# psoc4000t register map
Vendor: Cypress Semiconductor; Series: PSoC4000T; File version: 1.0
CPU: CM0PLUS r0p1, little endian, no MPU, no FPU, VTOR, 2 interrupt priority bits
Registers are 32-bit, read-write, reset 0x0 unless marked. A register's access mark holds for its fields unless they carry their own. Offsets are from the block's base; [hi:lo] are bit positions; lines under a group give offsets from that group; {n}, {i} and the like mark numbered series; 'fields as' and 'values as' point back to an identical list.

## MSCLP0 (part 2 of 3) — Low Power MultiSense Converter
Base 0x40290000
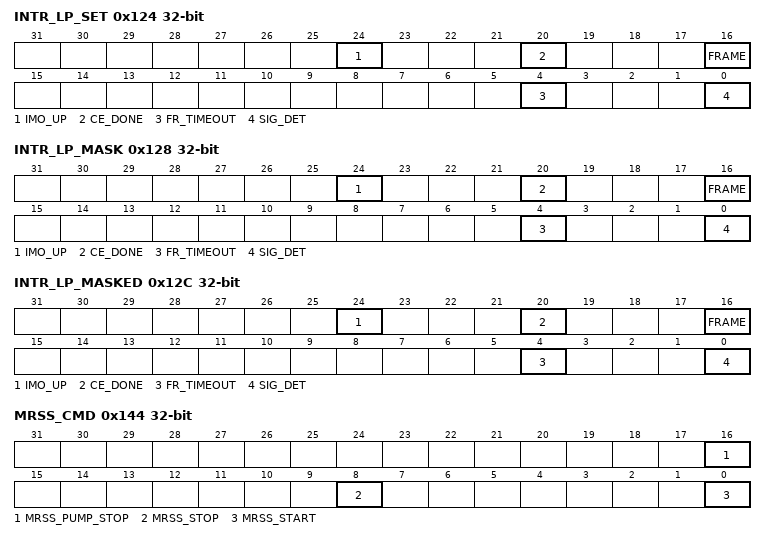
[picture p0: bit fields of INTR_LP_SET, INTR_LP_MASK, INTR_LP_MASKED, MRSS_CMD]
0x124 INTR_LP_SET — Low Power Interrupt Set Register
  [24] IMO_UP — Write with '1' to set corresponding bit in interrupt request register (a write of '0' has no effect).
  [20] CE_DONE — Write with '1' to set corresponding bit in interrupt request register (a write of '0' has no effect).
  [16] FRAME — Write with '1' to set corresponding bit in interrupt request register (a write of '0' has no effect).
  [4] FR_TIMEOUT — Write with '1' to set corresponding bit in interrupt request register (a write of '0' has no effect).
  [0] SIG_DET — Write with '1' to set corresponding bit in interrupt request register (a write of '0' has no effect).
0x128 INTR_LP_MASK — Low Power Interrupt Mask Register
  [24] IMO_UP — Mask bit for corresponding bit in interrupt cause register.
  [20] CE_DONE — Mask bit for corresponding bit in interrupt cause register.
  [16] FRAME — Mask bit for corresponding bit in interrupt cause register.
  [4] FR_TIMEOUT — Mask bit for corresponding bit in interrupt cause register.
  [0] SIG_DET — Mask bit for corresponding bit in interrupt cause register.
0x12C INTR_LP_MASKED ro — Low Power Interrupt Masked Register
  [24] IMO_UP — Logical AND of corresponding INTR_LP and INTR_LP_MASK bits.
  [20] CE_DONE — Logical AND of corresponding INTR_LP and INTR_LP_MASK bits.
  [16] FRAME — Logical AND of corresponding INTR_LP and INTR_LP_MASK bits.
  [4] FR_TIMEOUT — Logical AND of corresponding INTR_LP and INTR_LP_MASK bits.
  [0] SIG_DET — Logical AND of corresponding INTR_LP and INTR_LP_MASK bits.
0x140 WAKEUP_CMD — Wakeup Command Register
  [0] START_FRAME_AOS — Set by firmware to initiate frame scanning by the LP-AoS FSM (required for DEEP_SLEEP scanning). When detected, hardware clears the bit down and the LP-AoS FSM periodically scans all valid sensor configurations programmed in the sensor configuration storage starting from FRAME_CFG_START_ADDR. AoS Sequencer FSM clears this bit on egress from IDLE. If START_FRAME_AOS is set by firmware when FSM is not in IDLE, the hardware must hold the bit set to allow for 'pending' frame behaviour. Note that a rising edge on this bit also creates a 2x cycle clk_lf pulse on the msc_ext_frm_start_out signal (when EXT_FRAME_START_MODE = DISABLED). The corresponding msc_ext_frm_start_out_en is controlled by CTL.ENABLED.
0x144 MRSS_CMD — MRSS Command Register
  [16] MRSS_PUMP_STOP — Stop the MRSS pump resource. The ability to shut off the MRSS pump allows for power saving when MSCv3LP is in a standby state (CTL.ENABLED = 0) not scanning and hence no pump is needed. In this case the MRSS reference and IMO remain on so firmware may access MMIO in the SNS_STRUCTLP register bank. MRSS_STOP is used in the case where the entire MRSS is to be shut down. This bit is always read as 0.
  [8] MRSS_STOP — Stop the MRSS resources (shut down the reference, IMO and pump). This bit is always read as 0.
  [0] MRSS_START — Start the MRSS local resources. Activates logic on the clk_lf domain to boot up the MRSS resources. The boot up happens in sequence according to required timing specifications with reference, IMO (at frequencey IMO_CTL.FREQ) and pump (based on PUMP_CTL.PUMP_MODE). Firmware Rule: MRSS_START must be set by firmware to access any MMIO on the local IMO domain (SNS_STRUCTLP). This is not necessary in cases where the hardware has alread turned on the MRSS IMO and left it on (e.g. after DEEP_SLEEP interrupt the hardware leaves the IMO on with the expectation is that firmware intends to read SNS_STRUCTLP after such an interrupt).
0x180 MRSS_STATUS ro
  [0] MRSS_UP — Status bit to indicate whether the MRSS resources are booted or not. This booting may occur as the result of firmware intervention via MRSS_START/STOP or hardware based control via the LP-AoS FSM.
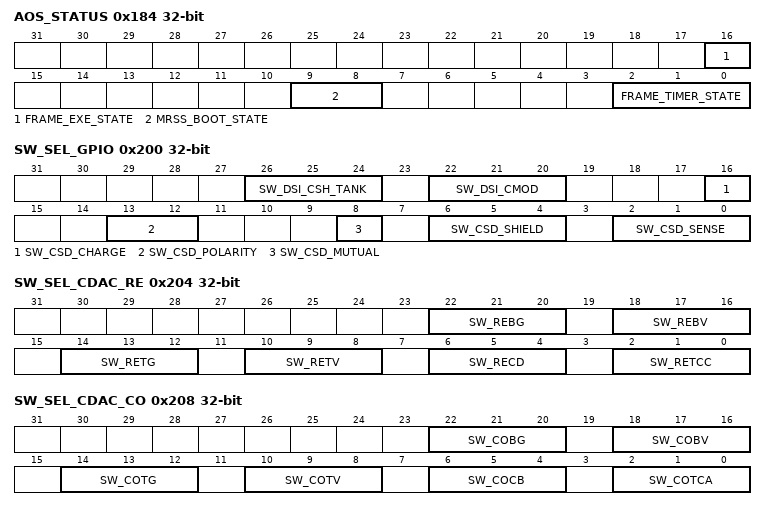
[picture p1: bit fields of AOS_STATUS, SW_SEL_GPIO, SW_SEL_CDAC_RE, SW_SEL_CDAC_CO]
0x184 AOS_STATUS ro
  [16] FRAME_EXE_STATE — LP-AoS Frame Execute FSM state. FSM runs on clk_imo_msc and no CDC implemented to AOS_STATUS (clk_sys).
    0=IDLE (N/A); 1=LP_EXE_FRAME (N/A)
  [9:8] MRSS_BOOT_STATE — LP-AoS MRSS Boot FSM state. FSM runs on clk_lf and no CDC implemented to AOS_STATUS (clk_sys).
    0=IDLE (N/A); 1=START_REF (N/A); 2=START_IMO (N/A); 3=START_PUMP (N/A)
  [2:0] FRAME_TIMER_STATE — LP-AoS Frame Timer FSM state. FSM runs on clk_lf and no CDC implemented to AOS_STATUS (clk_sys).
    0=IDLE (N/A); 1=WAIT_FRAME_INTERVAL (N/A); 2=WAIT_IMO (N/A); 3=LP_START_FRAME (N/A); 4=LP_WAIT_FRAME (N/A)
0x200 SW_SEL_GPIO — GPIO Switch Control
  [26:24] SW_DSI_CSH_TANK — MUX select for dsi_csh_tank waveform. if CMOD_SEL = CMOD_12 | CMOD_1 dsi_csh_tank[0] = Decode SW_DSI_CSH_TANK to select appropriate dsi_csh_tank waveform. dsi_csh_tank[1] = 0. if CMOD_SEL = CMOD_34 | CMOD_3 dsi_csh_tank[0] = 0. dsi_csh_tank[1] = Decode SW_DSI_CSH_TANK to select appropriate dsi_csh_tank waveform. This is assuming that: dsi_csh_tank[0] is routed to cmod2 dsi_csh_tank[1] is routed to cmod4 Hardware Overriding: Note that hardware overrides MMIO setting for dsi_csh_tank and sets it 1 during the INIT_SHORT state if using GPIO sensors (SW_DSI_CMOD != OPEN || SW_DSI_CSHTANK != OPEN).
    0=LOGIC_0 (N/A); 1=LOGIC_1 (N/A); 2=CHOP_PH0_PH1 (chop == 1 ? ph0 : ph1); 3=CHOP_PH1_PH3 (chop == 1 ? ph1 : ph3); 4=PH1 (N/A)
  [22:20] SW_DSI_CMOD — MUX select for dsi_cmod waveform. if CMOD_SEL = CMOD_12 | CMOD_1 dsi_cmod[0] = Decode SW_DSI_CMOD to select appropriate dsi_cmod waveform. dsi_cmod[1] = 0. if CMOD_SEL = CMOD_34 | CMOD_3 dsi_cmod[0] = 0. dsi_cmod[1] = Decode SW_DSI_CMOD to select appropriate dsi_cmod waveform. This is assuming that: dsi_cmod[0] is routed to cmod1 dsi_cmod[1] is routed to cmod3 Hardware Overriding: Note that hardware overrides MMIO setting for dsi_cmod and sets it 1 during the INIT_SHORT state if using GPIO sensors (SW_DSI_CMOD != OPEN || SW_DSI_CSHTANK != OPEN).
    0=LOGIC_0 (N/A); 1=LOGIC_1 (N/A); 2=CHOP_PH1_PH0 (chop == 1 ? ph1 : ph0); 3=CHOP_PH3_PH1 (chop == 1 ? ph3 : ph1); 4=PH0 (N/A)
  [16] SW_CSD_CHARGE — MUX select for csd_charge waveform.
    0=LOGIC_0 (N/A); 1=LOGIC_1 (N/A)
  [13:12] SW_CSD_POLARITY — MUX select for csd_polarity waveform.
    0=LOGIC_0 (N/A); 1=LOGIC_1 (N/A); 2=PH0_OR_PH1 (N/A)
  [8] SW_CSD_MUTUAL — MUX select for csd_mutual waveform.
    0=LOGIC_0 (N/A); 1=LOGIC_1 (N/A)
  [6:4] SW_CSD_SHIELD — MUX select for csd_shield waveform.
    0=LOGIC_0 (N/A); 1=LOGIC_1 (N/A); 2=PH0 (N/A); 3=PH1 (N/A); 4=PH0_OR_PH3 (N/A); 5=PH0_OR_FS2PH1_AND_PH1_OR_PH3 (ph0 || [Fs2_ph1 && (ph1 || ph3)]); 6=PH1X (N/A)
  [2:0] SW_CSD_SENSE — MUX select for csd_sense waveform.
    0=LOGIC_0 (N/A); 1=LOGIC_1 (N/A); 2=PH0 (N/A); 3=PH1 (N/A); 4=PH0_OR_PH3 (N/A); 5=PH0X (N/A); 6=PH1X (N/A)
0x204 SW_SEL_CDAC_RE — Reference CAPDAC Switch Control
  [22:20] SW_REBG — Reference CAPDAC bottom plate to vssa_q Switch. Firmware Rule: Do not program REBV and REBG such that they are closed simultaneously. Hardware Overriding: See SEL_RE register description.
    0=OPEN (sel = 00); 1=CLOSED (sel = 01); 2=CLK (sel = 10 (clk_reffb)); 3=CLK_BAR (sel = 11 (!clk_reffb)); 4=PH1X (DFT mode (ph1X ? sel = 01 : sel = 00))
  [18:16] SW_REBV — Reference CAPDAC bottom plate to vdda_q Switch. Firmware Rule: Do not program REBV and REBG such that they are closed simultaneously. Hardware Overriding: See SEL_RE register description.
    0=OPEN (sel = 00); 1=CLOSED (sel = 01); 2=CLK (sel = 10 (clk_reffb)); 3=CLK_BAR (sel = 11 (!clk_reffb)); 4=PH0X (DFT mode (ph0X ? sel = 01 : sel = 00))
  [14:12] SW_RETG — Reference CAPDAC top plate to vssa_q Switch. Firmware Rule: Do not program RETV and RETG such that they are closed simultaneously. Hardware Overriding: See SEL_RE register description.
    0=OPEN (sel = 00); 1=CLOSED (sel = 01); 2=CLK (sel = 10 (clk_reffb)); 3=CLK_BAR (sel = 11 (!clk_reffb)); 4=PH0 (DFT mode (ph0 ? sel = 01 : sel = 00)); 5=PH2 (DFT mode (ph2 ? sel = 01 : sel = 00))
  [10:8] SW_RETV — Reference CAPDAC top plate to vdda_q Switch. Firmware Rule: Do not program RETV and RETG such that they are closed simultaneously. Hardware Overriding: See SEL_RE register description.
    values as SW_RETG
  [6:4] SW_RECD — Reference CAPDAC to CSD Bus D Switch. Hardware Overriding: See SEL_RE register description.
    0=OPEN (sel = 00); 1=CLOSED (sel = 01); 2=CHOP_CLK_BAR (chop == 0 ? sel = 10 (clk_reffb) : sel = 11 (!clk_reffb)); 3=CHOP_CLK (chop == 1 ? sel = 10 (clk_reffb) : sel = 11 (!clk_reffb)); 4=PH1 (DFT mode (ph1 ? sel = 01 : sel = 00)); 5=PH3 (DFT mode (ph3 ? sel = 01 : sel = 00))
  [2:0] SW_RETCC — Reference CAPDAC top plate to CSD Bus C Switch. Hardware Overriding: See SEL_RE register description.
    0=OPEN (sel = 00); 1=CLOSED (sel = 01); 2=CHOP_CLK_BAR (chop == 0 ? sel = 10 (clk_reffb) : sel = 11 (!clk_reffb)); 3=CHOP_CLK (chop == 1 ? sel = 10 (clk_reffb) : sel = 11 (!clk_reffb)); 4=PH1 (DFT mode (ph1 ? sel = 01 : sel = 00)); 5=PH3 (DFT mode (ph3 ? sel = 01 : sel = 00)); 6=PH0 (DFT mode (ph0 ? sel = 01 : sel = 00))
0x208 SW_SEL_CDAC_CO — Compensation CAPDAC Switch Control
  [22:20] SW_COBG — Compensation CAPDAC bottom plate to vssa_q Switch. Firmware Rule: Do not program COBV and COBG such that they are closed simultaneously. Hardware Overriding: See SEL_CO, COMP_BLANKING_EN register description.
    0=OPEN (sel = 00); 1=CLOSED (sel = 01); 2=CLK (sel = 10 (clk_comp)); 3=CLK_BAR (sel = 11 (!clk_comp)); 4=PH1X (DFT mode (ph1X ? sel = 01 : sel = 00))
  [18:16] SW_COBV — Compensation CAPDAC bottom plate to vdda_q Switch. Firmware Rule: Do not program COBV and COBG such that they are closed simultaneously. Hardware Overriding: See SEL_CO, COMP_BLANKING_EN register description.
    0=OPEN (sel = 00); 1=CLOSED (sel = 01); 2=CLK (sel = 10 (clk_comp)); 3=CLK_BAR (sel = 11 (!clk_comp)); 4=PH0X (DFT mode (ph0X ? sel = 01 : sel = 00))
  [14:12] SW_COTG — Compensation CAPDAC top plate to vssa_q Switch. Firmware Rule: Do not program COTV and COTG such that they are closed simultaneously. Hardware Overriding: See SEL_CO, COMP_BLANKING_EN register description.
    values as SW_SEL_CDAC_RE.SW_RETG
  [10:8] SW_COTV — Compensation CAPDAC top plate to vdda_q Switch. Firmware Rule: Do not program COTV and COTG such that they are closed simultaneously. Hardware Overriding: See SEL_CO, COMP_BLANKING_EN register description.
    values as SW_SEL_CDAC_RE.SW_RETG
  [6:4] SW_COCB — Compensation CAPDAC to CSD Bus B Switch. Hardware Overriding: Note during the PRO_OFFSET state the following autonomous overriding occurs: (compout_sync ^ CHOP_POL) ? [sel = 10 (clk_comp) ] : [sel = 11 (!clk_comp)]. Note that the CHOP_POL above is the hardware copy of the current chop polarity. Additionally see SEL_CO, COMP_BLANKING_EN register description.
    0=OPEN (sel = 00); 1=CLOSED (sel = 01); 2=CHOP_CLK_BAR (chop == 0 ? sel = 10 (clk_comp) : sel = 11 (!clk_comp)); 3=CHOP_CLK (chop == 1 ? sel = 10 (clk_comp) : sel = 11 (!clk_comp)); 4=PH1 (DFT mode (ph1 ? sel = 01 : sel = 00)); 5=PH3 (DFT mode (ph3 ? sel = 01 : sel = 00))
  [2:0] SW_COTCA — Compensation CAPDAC top plate to CSD Bus A Switch. Hardware Overriding: Note during the PRO_OFFSET state the following autonomous overriding occurs: (compout_sync ^ CHOP_POL) ? [sel = 11 (!clk_comp) ] : [sel = 10 (clk_comp)]. Note that the CHOP_POL above is the hardware copy of the current chop polarity. Additionally see SEL_CO, COMP_BLANKING_EN register description.
    0=OPEN (sel = 00); 1=CLOSED (sel = 01); 2=CHOP_CLK_BAR (chop == 0 ? sel = 10 (clk_comp) : sel = 11 (!clk_comp)); 3=CHOP_CLK (chop == 1 ? sel = 10 (clk_comp) : sel = 11 (!clk_comp)); 4=PH1 (DFT mode (ph1 ? sel = 01 : sel = 00)); 5=PH3 (DFT mode (ph3 ? sel = 01 : sel = 00)); 6=PH0 (DFT mode (ph0 ? sel = 01 : sel = 00))
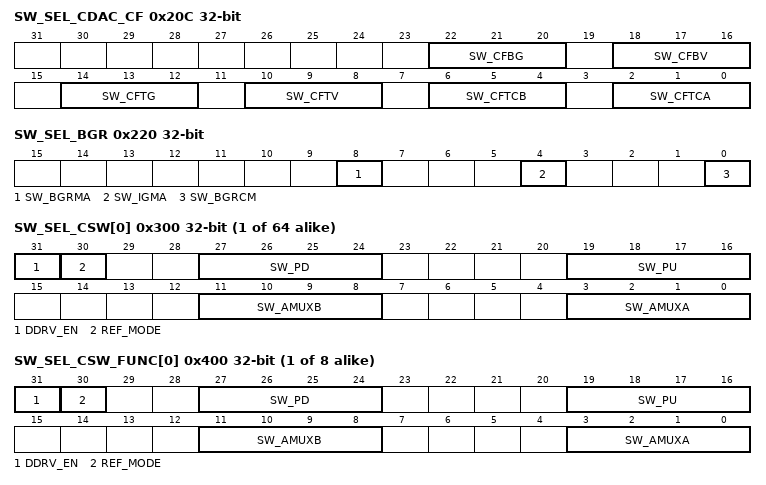
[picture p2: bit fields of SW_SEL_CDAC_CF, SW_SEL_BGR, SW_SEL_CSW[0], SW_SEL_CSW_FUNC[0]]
0x20C SW_SEL_CDAC_CF — Fine CAPDAC Switch Control
  [22:20] SW_CFBG — Fine CAPDAC bottom plate to vssa_q Switch. Firmware Rule: Do not program CFBV and CFBG such that they are closed simultaneously. Hardware Overriding: See SEL_CF, COMP_BLANKING_EN register description.
    0=OPEN (sel = 00); 1=CLOSED (sel = 01); 2=CLK (FINE_MODE == REFERENCE ? sel = 10 (clk_reffb) : sel = 10 (clk_comp)); 3=CLK_BAR (FINE_MODE == REFERENCE ? sel = 11 (!clk_reffb) : sel = 11 (!clk_comp)); 4=PH1X (DFT mode (ph1X ? sel = 01 : sel = 00))
  [18:16] SW_CFBV — Fine CAPDAC bottom plate to vdda_q Switch. Firmware Rule: Do not program CFBV and CFBG such that they are closed simultaneously. Hardware Overriding: See SEL_CF, COMP_BLANKING_EN register description.
    0=OPEN (sel = 00); 1=CLOSED (sel = 01); 2=CLK (FINE_MODE == REFERENCE ? sel = 10 (clk_reffb) : sel = 10 (clk_comp)); 3=CLK_BAR (FINE_MODE == REFERENCE ? sel = 11 (!clk_reffb) : sel = 11 (!clk_comp)); 4=PH0X (DFT mode (ph0X ? sel = 01 : sel = 00))
  [14:12] SW_CFTG — Fine CAPDAC top plate to vssa_q Switch. Firmware Rule: Do not program CFTV and CFTG such that they are closed simultaneously. Hardware Overriding: See SEL_CF register description.
    0=OPEN (sel = 00); 1=CLOSED (sel = 01); 2=CLK (sel = 10 [(FINE_MODE == REFERENCE) ? clk_reffb : clk_comp]); 3=CLK_BAR (sel = 11 [(FINE_MODE == REFERENCE) ? !clk_reffb : !clk_comp]); 4=PH0 (DFT mode (ph0 ? sel = 01 : sel = 00)); 5=PH2 (DFT mode (ph2 ? sel = 01 : sel = 00))
  [10:8] SW_CFTV — Fine CAPDAC top plate to vdda_q Switch. Firmware Rule: Do not program CFTV and CFTG such that they are closed simultaneously. Hardware Overriding: See SEL_CF, COMP_BLANKING_EN register description.
    values as SW_CFTG
  [6:4] SW_CFTCB — Fine CAPDAC top plate to CSD Bus B Switch. Hardware Overriding: Note during the PRO_OFFSET state the following autonomous overriding occurs if FINE_MODE = COMPENSATION: (compout_sync ^ CHOP_POL) ? [sel = 10 (clk_comp) ] : [sel = 11 (!clk_comp)]. Note that the CHOP_POL above is the hardware copy of the current chop polarity. Hardware Overriding: See SEL_CO, COMP_BLANKING_EN register description.
    0=OPEN (sel = 00); 1=CLOSED (sel = 01); 2=CHOP_CLK_BAR (case({chop,FINE_MODE}) {1,REFERENCE} : sel = 11 (!clk_reffb) {1,COMPENSATION} : sel = 11 (!clk_comp) {0,REFERENCE} : sel = 10 (clk_reffb) {0,COMPENSATION} : sel = 10 (clk_comp)); 3=CHOP_CLK (case({chop,FINE_MODE}) {1,REFERENCE} : sel = 10 (clk_reffb) {1,COMPENSATION} : sel = 10 (clk_comp) {0,REFERENCE} : sel = 11 (!clk_reffb) {0,COMPENSATION} : sel = 11 (!clk_comp)); 4=PH1 (DFT mode (ph1 ? sel = 01 : sel = 00)); 5=PH3 (DFT mode (ph3 ? sel = 01 : sel = 00)); 6=PH0 (DFT mode (ph0 ? sel = 01 : sel = 00))
  [2:0] SW_CFTCA — Fine CAPDAC top plate to CSD Bus A Switch. Hardware Overriding: Note during the PRO_OFFSET state the following autonomous overriding occurs if FINE_MODE = COMPENSATION: (compout_sync ^ CHOP_POL) ? [sel = 11 (!clk_comp) ] : [sel = 10 (clk_comp)]. Note that the CHOP_POL above is the hardware copy of the current chop polarity. Additionally see SEL_CF, COMP_BLANKING_EN register description.
    values as SW_CFTCB
0x220 SW_SEL_BGR — Bandgap Reference Switch Control
  [all] fields
    0=OPEN (N/A); 1=CLOSED (N/A)
  [8] SW_BGRMA — Connect buffered 1.2V reference to ADFT pin via AMUXBUSA. For DFT purposes.
  [4] SW_IGMA — Connect 48uA ganged IREF to ADFT pin via AMUXBUSA. For DFT purposes.
  [0] SW_BGRCM — BandGap reference to Comparator minus terminal switch. This switch can be used for firmware vdda level detection to facilitate appropriate configuration of the local pump and pump regulator.
{0x300+4i} SW_SEL_CSW[{i}] (i=0..63) — CapSense Sensor Switch Control
  [31] DDRV_EN — MutliSense GPIO Sensor N digital driver enable in MSC specific GPIO. Firmware Rule: When using the digital driver, the GPIO MSC analog cannot be used (GPIO port register MSC_ANA.DATAx for port pin x should be set 0).
    0=DISABLED (N/A); 1=ENABLED (N/A)
  [30] REF_MODE — MutliSense GPIO Sensor N is used as a reference. Hardware Overriding: If REF_MODE = 0, SW_AMUXA, SW_AMUXB, SW_PU and SW_PD are all forced OPEN duing PRO_OFFSET, PRO_WAIT, EPILOGUE and POST_EPI to disconnect the sensor.
    0=DISABLED (N/A); 1=ENABLED (N/A)
  [27:24] SW_PD — MultiSense GPIO Sensor N pull down to vssa_q Switch. Switch exists in MSC specific GPIO. Firmware Rule: Do not program PU and PD such that they are closed simultaneously. Hardware Overriding: If this sensor is a FW CSX TXP pin (SW_PU == PH0X && SW_PD == PH1X), SW_PD is CLOSED during INIT_CMOD and INIT_SHORT if in full wave mode (CMOD_SEL = CMOD_12||CMOD_34 && INIT_MODE = REFERENCE_VDDA).
    0=OPEN (N/A); 1=CLOSED (N/A); 2=PH0 (N/A); 3=PH1 (N/A); 4=PH2 (N/A); 5=PH1_OR_PH3 (N/A); 6=PH2_OR_PH3 (N/A); 7=PH0X (N/A); 8=PH1X (N/A); 9=PH2_OR_FS2PH1_AND_PH1_OR_PH3 (ph2 || [Fs2_ph1 && (ph1 || ph3)]); 10=CLK_BAR (clk_extfb_bar); 11=PH1_OR_PH2 (Note SENSE_DUTY_CTL digital non-overlap control has no impact on this waveform.); 12=PH0_OR_PH3 (Note SENSE_DUTY_CTL digital non-overlap control has no impact on this waveform.)
  [19:16] SW_PU — MultiSense GPIO Sensor N pull up to vdda_q Switch. Switch exists in MSC specific GPIO. Also drives the MSC specific GPIO digital driver (enable controlled by DDRV_EN). Firmware Rule: Do not program PU and PD such that they are closed simultaneously. Hardware Overriding: If this sensor is a FW CSX TXN pin (SW_PU == PH1X && SW_PD == PH0X), SW_PU is CLOSED during INIT_CMOD and INIT_SHORT if in full wave mode (CMOD_SEL = CMOD_12||CMOD_34 && INIT_MODE = REFERENCE_VDDA).
    0=OPEN (N/A); 1=CLOSED (N/A); 2=PH0 (N/A); 3=PH1 (N/A); 4=PH2 (N/A); 5=PH0_OR_PH1 (N/A); 6=PH0X (N/A); 7=PH1X (N/A); 8=PH0_OR_FS2PH0_AND_PH1_OR_PH3 (ph0 || [Fs2_ph0 && (ph1 || ph3)]); 9=CLK (clk_extfb); 10=PH0X_BAR; 11=PH1_OR_PH2 (Note SENSE_DUTY_CTL digital non-overlap control has no impact on this waveform.); 12=PH0_OR_PH3 (Note SENSE_DUTY_CTL digital non-overlap control has no impact on this waveform.)
  [11:8] SW_AMUXB — MultiSense GPIO Sensor N to AMUXBUSB Switch. Switch exists in MSC specific GPIO. Hardware Overriding: If this sensor is a full wave CSD RX pin or a FW CSD Cs pin ((CMOD_SEL = CMOD_12||CMOD_34) && INIT_MODE = REFERENCE_VDDA && SW_AMUXA != OPEN), then SW_AMUXB is set CLOSED during INIT_CMOD.
    0=OPEN (N/A); 1=CLOSED (N/A); 2=CHOP_TWO_PHASE (chop == 0 ? ph1 : ph0); 3=CHOP_FOUR_PHASE (chop == 0 ? ph3 : ph1); 4=CHOP_MPSC_D (chop == 0 ? ph1 : ph3); 5=CHOP_MPRX (chop == 0 ? ph0 : ph1); 6=PH0 (N/A); 7=PH2 (N/A); 8=CHOP_CLK_BAR (chop == 0 ? clk_extfb : clk_extfb_bar); 9=CHOP_CLK (chop == 1 ? clk_extfb : clk_extfb_bar); 10=PH1_OR_PH3 (N/A)
  [3:0] SW_AMUXA — MultiSense GPIO Sensor N to AMUXBUSA Switch. Switch exists in MSC specific GPIO. Hardware Overriding: Note that hardware overrides MMIO setting for SW_AMUXA and sets it CLOSED during the INIT_SHORT state if MMIO has programmed SW_AMUXA != OPEN (i.e. this sensor is being used). The same overriding applies during INIT_CMOD, but only in half-wave mode (CMOD_SEL = CMOD_1 or CMOD_3).
    0=OPEN (N/A); 1=CLOSED (N/A); 2=CHOP_TWO_PHASE (chop == 0 ? ph0 : ph1); 3=CHOP_FOUR_PHASE (chop == 0 ? ph1 : ph3); 4=CHOP_MPSC_D (chop == 0 ? ph3 : ph1); 5=CHOP_MPRX (chop == 0 ? ph1 : ph0); 6=PH1 (N/A); 7=PH3 (N/A); 8=CHOP_CLK_BAR (chop == 0 ? clk_extfb : clk_extfb_bar); 9=CHOP_CLK (chop == 1 ? clk_extfb : clk_extfb_bar); 10=PH1_OR_PH3 (N/A)
{0x400+4i} SW_SEL_CSW_FUNC[{i}] (i=0..7) — CapSense Sensor Switch Control Global Functions
  [31] DDRV_EN — MutliSense GPIO Sensor N digital driver enable in MSC specific GPIO. Firmware Rule: When using the digital driver, the GPIO MSC analog cannot be used (GPIO port register MSC_ANA.DATAx for port pin x should be set 0).
    0=DISABLED (N/A); 1=ENABLED (N/A)
  [30] REF_MODE — MultiSense GPIO Sensor is used as a reference. Hardware Overriding: If REF_MODE = 0, SW_AMUXA, SW_AMUXB, SW_PU and SW_PD are all forced OPEN duing PRO_OFFSET, PRO_WAIT, EPILOGUE and POST_EPI to disconnect the sensor.
    0=DISABLED (N/A); 1=ENABLED (N/A)
  [27:24] SW_PD — MultiSense GPIO Sensor pull down to vssa_q Switch. Switch exists in MSC specific GPIO. Firmware Rule: Do not program PU and PD such that they are closed simultaneously. Hardware Overriding: If this sensor is a FW CSX TXP pin (SW_PU == PH0X && SW_PD == PH1X), SW_PD is CLOSED during INIT_CMOD and INIT_SHORT if in full wave mode (CMOD_SEL = CMOD_12||CMOD_34 && INIT_MODE = REFERENCE_VDDA).
    values as SW_SEL_CSW[0].SW_PD
  [19:16] SW_PU — MultiSense GPIO Sensor pull up to vdda_q Switch. Switch exists in MSC specific GPIO. Also drives the MSC specific GPIO digital driver (enable controlled by DDRV_EN). Firmware Rule: Do not program PU and PD such that they are closed simultaneously. Hardware Overriding: If this sensor is a FW CSX TXN pin (SW_PU == PH1X && SW_PD == PH0X), SW_PU is CLOSED during INIT_CMOD and INIT_SHORT if in full wave mode (CMOD_SEL = CMOD_12||CMOD_34 && INIT_MODE = REFERENCE_VDDA).
    values as SW_SEL_CSW[0].SW_PU
  [11:8] SW_AMUXB — MultiSense GPIO Sensor N to AMUXBUSB Switch. Switch exists in MSC specific GPIO. Hardware Overriding: If this sensor is a full wave CSD RX pin or a FW CSD Cs pin ((CMOD_SEL = CMOD_12||CMOD_34) && INIT_MODE = REFERENCE_VDDA && SW_AMUXA != OPEN), then SW_AMUXB is set CLOSED during INIT_CMOD.
    values as SW_SEL_CSW[0].SW_AMUXB
  [3:0] SW_AMUXA — MultiSense GPIO Sensor to AMUXBUSA Switch. Switch exists in MSC specific GPIO. Hardware Overriding: Note that hardware overrides MMIO setting for SW_AMUXA and sets it CLOSED during the INIT_SHORT state if MMIO has programmed SW_AMUXA != OPEN (i.e. this sensor is being used). The same overriding applies during INIT_CMOD, but only in half-wave mode (CMOD_SEL = CMOD_1 or CMOD_3).
    values as SW_SEL_CSW[0].SW_AMUXA
0x500 CSW_CTL_LO — CapSense Sensor Switch Control Low
  [31:0] CSW_FUNC_MODE — Select between SW_SEL_CSW[x] and SW_SEL_CSW_FUNC. CSW_FUNC_MODE[x] = 0: Use SW_CSW_CTL for control MUX x. CSW_FUNC_MODE[x] = 1: Use SW_SEL_CSW_FUNC[y] for control MUX x as selected by y = {SW_SEL_CSW_MASK2[x],SW_SEL_CSW_MASK1[x],SW_SEL_CSW_MASK0[x]}.
0x504 CSW_CTL_HI — CapSense Sensor Switch Control High
  fields as CSW_CTL_LO
{0x600+0x40*i} MODE[{i}] (i=0..2) group — Sense Mode Configuration Structure
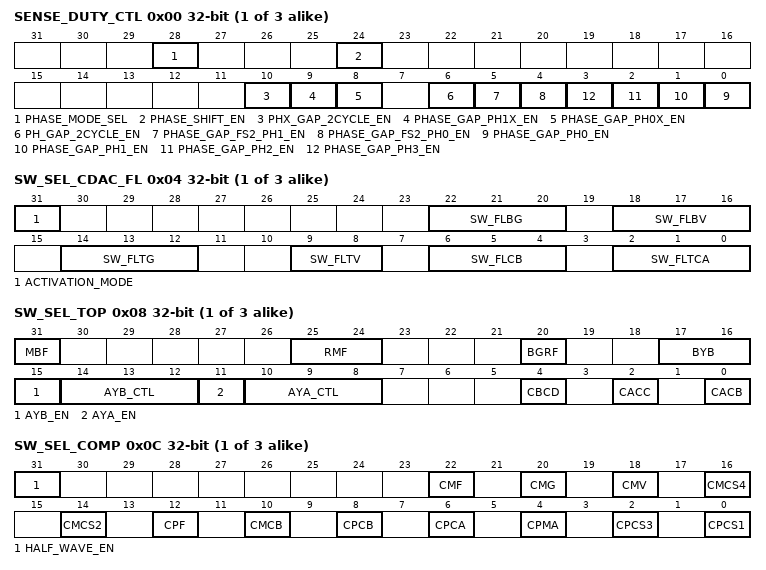
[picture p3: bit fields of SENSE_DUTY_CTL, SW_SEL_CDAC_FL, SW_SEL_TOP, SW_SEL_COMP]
  0x00 SENSE_DUTY_CTL — Sense Clock Duty Cycle Control
    [28] PHASE_MODE_SEL — Select 4-phase or 2-phase mode. '0': Four phase. '1': Two phase.
      0=FOUR_PHASE (N/A); 1=TWO_PHASE (N/A)
    [24] PHASE_SHIFT_EN — Enable phase shift logic that generates the Ph0X and Ph1X waveforms. Used for inductive and impedance sensing. If enabled, PHASE_SHIFT_CYCLES must be > 0.
      0=DISABLED (N/A); 1=ENABLED (N/A)
    [10] PHX_GAP_2CYCLE_EN — If set, applies a two cycle gap on ph0X/ph1X if the corresponding PHASE_GAP_*_EN is set.
      0=ONE_CYCLE (N/A); 1=TWO_CYCLE (N/A)
    [9] PHASE_GAP_PH1X_EN — Decide whether clk_mod cycle non-overlap gap is applied at the end of ph1x. PHASE_GAP_PH1X_EN = 0 -> No gap. PHASE_GAP_PH1X_EN = 1 && PHX_GAP_2CYCLE_EN = 0 -> 1x cycle gap. PHASE_GAP_PH1X_EN = 1 && PHX_GAP_2CYCLE_EN = 1 -> 2x cycle gap. Does not apply to signals controlled by SW_SEL_CSD and SW_SEL_DSI since GPIO has in-built non-overlap circuitry.
      0=DISABLED (N/A); 1=ENABLED (N/A)
    [8] PHASE_GAP_PH0X_EN — Decide whether clk_mod cycle non-overlap gap is applied at the end of ph0x. PHASE_GAP_PH0X_EN = 0 -> No gap. PHASE_GAP_PH0X_EN = 1 && PHX_GAP_2CYCLE_EN = 0 -> 1x cycle gap. PHASE_GAP_PH0X_EN = 1 && PHX_GAP_2CYCLE_EN = 1 -> 2x cycle gap. Does not apply to signals controlled by SW_SEL_CSD and SW_SEL_DSI since GPIO has in-built non-overlap circuitry.
      0=DISABLED (N/A); 1=ENABLED (N/A)
    [6] PH_GAP_2CYCLE_EN — If set, applies a two cycle gap on ph0/ph1/ph2/ph3/Fs2_ph0/Fs2_ph1 if the corresponding PHASE_GAP_*_EN is set.
      0=ONE_CYCLE (N/A); 1=TWO_CYCLE (N/A)
    [5] PHASE_GAP_FS2_PH1_EN — Decide whether clk_mod cycle non-overlap gap is applied at the end of Fs2_ph0. PHASE_GAP_FS2_PH1_EN = 0 -> No gap. PHASE_GAP_FS2_PH1_EN = 1 && PH_GAP_2CYCLE_EN = 0 -> 1x cycle gap. PHASE_GAP_FS2_PH1_EN = 1 && PH_GAP_2CYCLE_EN = 1 -> 2x cycle gap. Does not apply to signals controlled by SW_SEL_CSD and SW_SEL_DSI since GPIO has in-built non-overlap circuitry.
      0=DISABLED (N/A); 1=ENABLED (N/A)
    [4] PHASE_GAP_FS2_PH0_EN — Decide whether clk_mod cycle non-overlap gap is applied at the end of Fs2_ph0. PHASE_GAP_FS2_PH0_EN = 0 -> No gap. PHASE_GAP_FS2_PH0_EN = 1 && PH_GAP_2CYCLE_EN = 0 -> 1x cycle gap. PHASE_GAP_FS2_PH0_EN = 1 && PH_GAP_2CYCLE_EN = 1 -> 2x cycle gap. Does not apply to signals controlled by SW_SEL_CSD and SW_SEL_DSI since GPIO has in-built non-overlap circuitry.
      0=DISABLED (N/A); 1=ENABLED (N/A)
    [n] PHASE_GAP_PH{n}_EN (n=0..3) — Decide whether clk_mod cycle non-overlap gap is applied at the end of ph{n}. PHASE_GAP_PH{n}_EN = 0 -> No gap. PHASE_GAP_PH{n}_EN = 1 && PH_GAP_2CYCLE_EN = 0 -> 1x cycle gap. PHASE_GAP_PH{n}_EN = 1 && PH_GAP_2CYCLE_EN = 1 -> 2x cycle gap. Does not apply to signals controlled by SW_SEL_CSD and SW_SEL_DSI since GPIO has in-built non-overlap circuitry.
      0=DISABLED (N/A); 1=ENABLED (N/A)
  0x04 SW_SEL_CDAC_FL — Flatspot/Dither CAPDAC Switch Control
    [31] ACTIVATION_MODE — Activation event for Dither/Flatspot LFSR. '0': Clock LFSR on ph0. '1': Clock LFSR on ph0 or ph2. Notes: PH0 activation can be used in both 2 and 4 phase mode (PHASE_MODE_SEL). PH0_OR_PH2 activation can be used in 4 phase mode only (PHASE_MODE_SEL). In PH0 activation mode, the LFSR clocks on ph0 only. However hardware autonomously intervenes by processing the LFSR MSB before routing to the HardIP as follows during any given sense period: PHASE_MODE_SEL = TWO_PHASE: Invert LFSR MSB on ph1 rising edge. PHASE_MODE_SEL = FOUR_PHASE: Invert LFSR MSB on ph2 rising edge.
      0=PH0 (N/A); 1=PH0_OR_PH2 (N/A)
    [22:20] SW_FLBG — Flatspot/Dither CAPDAC bottom plate to vssa_q Switch. Firmware Rule: Do not program FLBV and FLBG such that they are closed simultaneously. Hardware Overriding: Notes: 1) Equations below describe 'msb' term as raw LFSR output, and take into account overriding as defined by ACTIVATION_MODE. 2) Glitches on FLBV or FLBG during ph0 or ph2 are acceptable (if msb toggles at this time) as the FLTCA and FLCB switches are open during this phase so there is no connection into the comparator or the Cmod caps. 3) See description of FL_MODE register.
      0=OPEN (N/A); 1=CLOSED (N/A); 2=PH0X (N/A); 3=PH1X (N/A); 4=PRECHARGE_2_PH ([(msb^ph1)^(ph0||ph1)] & [ph0||ph1]); 5=PRECHARGE_2_PH_BAR ((![(msb^ph1)^(ph0||ph1)]) & [ph0||ph1]); 6=PRECHARGE_4_PH ([(msb^(ph2||ph3))^(ph0||ph2)] & [ph0||ph1||ph2||ph3]); 7=PRECHARGE_4_PH_BAR ((![(msb^(ph2||ph3))^(ph0||ph2)]) & [ph0||ph1||ph2||ph3])
    [18:16] SW_FLBV — Flatspot/Dither CAPDAC bottom plate to vdda_q Switch. Firmware Rule: Do not program FLBV and FLBG such that they are closed simultaneously. Hardware Overriding: Notes: 1) Equations below describe 'msb' term as raw LFSR output, and take into account overriding as defined by ACTIVATION_MODE. 2) Glitches on FLBV or FLBG during ph0 or ph2 are acceptable (if msb toggles at this time) as the FLTCA and FLCB switches are open during this phase so there is no connection into the comparator or the Cmod caps. 3) See description of FL_MODE register.
      values as SW_FLBG
    [14:12] SW_FLTG — Flatspot/Dither CAPDAC top plate to vssa_q Switch. Firmware Rule: Do not program FLTV and FLTG such that they are closed simultaneously. Hardware Overriding: See description of FL_MODE register.
      0=OPEN (N/A); 1=CLOSED (N/A); 2=PH1 (N/A); 3=PH0_OR_PH2 (N/A); 4=PH0 (DFT mode); 5=PH2 (DFT mode)
    [9:8] SW_FLTV — Flatspot/Dither CAPDAC top plate to vdda_q Switch. Firmware Rule: Do not program FLTV and FLTG such that they are closed simultaneously. Hardware Overriding: See description of FL_MODE register.
      0=OPEN (N/A); 1=CLOSED (N/A); 2=PH0 (DFT mode); 3=PH2 (DFT mode)
    [6:4] SW_FLCB — Flatspot/Dither CAPDAC to CSD Bus B Switch. Hardware Overriding: See description of FL_MODE register.
      0=OPEN (N/A); 1=CLOSED (N/A); 2=CHOP_PH1_4PHASE (chop == 1 ? ph1 : ph3); 3=CHOP_PH3 (chop == 1 ? ph3 : ph1); 4=CHOP_PH0 (chop == 1 ? ph0 : ph1); 5=CHOP_PH1_2PHASE (chop == 1 ? ph1 : ph0)
    [2:0] SW_FLTCA — Flatspot/Dither CAPDAC top plate to CSD Bus A Switch. Hardware Overriding: See description of FL_MODE register.
      values as SW_FLCB
  0x08 SW_SEL_TOP — Top Level Switch Control
    [31] MBF — AMUXBUSB to Filter Switch
      0=OPEN (N/A); 1=CLOSED (N/A)
    [25:24] RMF — Ratiometric Reference to Filter Switch. Connect a tap off from the resistor divider to the input of the RC filter. This tap off point is programmable.
      0=OFF (Resistor divider off.); 1=VDDA_X_0P5 (vdda/2); 2=VDDA_X_0P3 (vdda*0.3 (Used to detect when vdda=4V then resistor divider will output 1.2V)); 3=VDDA_X_0P8 (vdda*0.8)
    [20] BGRF — Bandgap Reference to Filter Switch
      0=OPEN (N/A); 1=CLOSED (N/A)
    [17:16] BYB — AMUXBUS B to CSD Bus B Switch. This register is wired to the hard IP directly (no MUX required in soft IP). Hardware Overriding: If full wave mode (CMOD_SEL = CMOD_12 || CMOD_34), and either SW_SEL_CMOD2.SW_AMUXB != OPEN or SW_SEL_CMOD4.SW_AMUXB != OPEN, then BYB set CLOSED during INIT_SHORT.
      0=OPEN_ISOLATED (sel = 00); 1=OPEN_NON_ISOLATED_CSDBUS (sel = 01); 2=OPEN_NON_ISOLATED_AMUXBUS (sel = 10); 3=CLOSED (sel = 11)
    [15] AYB_EN — AMUXBUS A to CSD Bus B Switch. Controls first part of AYB switch (AYB_EN<0> on the hardIP). This register is wired to the hard IP directly (no MUX required in soft IP). Hardware Overriding: See CMOD_SEL and INIT_MODE for INIT_CMOD phase half-wave initialisation behaviour. If full wave mode and the corresponding AMUXB switch is not open ((CMOD_SEL == CMOD_12 && SW_SEL_CMOD2.SW_AMUXB != OPEN) || (CMOD_SEL == CMOD_34 && SW_SEL_CMOD4.SW_AMUXB != OPEN)), then AYB_EN set CLOSED during INIT_SHORT.
      0=OPEN_ISOLATED (Opens first part of AYB switch. Enables isolation on AYB if AYB_CTL is also OPEN.); 1=CLOSED (Closes first part of AYB switch and disables isolation.)
    [14:12] AYB_CTL — AMUXBUS A to CSD Bus B Switch. Controls second part of AYB switch (AYB_EN<1> on hardIP). Alternative to using dsi_csh_tank in legacy HSIOM GPIO mode. Hardware Overriding: See CMOD_SEL and INIT_MODE for INIT_CMOD phase half-wave initialisation behaviour. If full wave mode and the corresponding AMUXB switch is not open ((CMOD_SEL == CMOD_12 && SW_SEL_CMOD2.SW_AMUXB != OPEN) || (CMOD_SEL == CMOD_34 && SW_SEL_CMOD4.SW_AMUXB != OPEN)), then AYB_CTL set CLOSED during INIT_SHORT.
      0=OPEN (Opens second part of AYB switch. Enables isolation on AYB if AYB_EN is also OPEN_ISOLATED.); 1=CLOSED (N/A); 2=CHOP_TWO_PHASE (chop == 0 ? ph1 : ph0); 3=CHOP_FOUR_PHASE (chop == 0 ? ph3 : ph1); 4=CHOP_MPSC_D (chop == 0 ? ph1 : ph3); 5=CHOP_MPRX (chop == 0 ? ph0 : ph1); 6=PH0 (N/A); 7=PH2 (N/A)
    [11] AYA_EN — AMUXBUS A to CSD Bus A Switch. Controls the first part of AYA switch (AYA_EN<0> on the hardIP). Hardware Overriding: Note that hardware overrides MMIO setting for AYA_EN and sets it CLOSED during the INIT_SHORT state. This register is wired to the hard IP directly (no MUX required in soft IP).
      0=OPEN_ISOLATED (Opens first part of AYA switch. Enables isolation on AYA if AYA_CTL is also OPEN.); 1=CLOSED (Closes first part of AYA switch and disables isolation.)
    [10:8] AYA_CTL — AMUXBUS A to CSD Bus A Switch. Controls second part of AYA switch (AYA_EN<1> on hardIP). Alternative to using dsi_cmod in legacy HSIOM GPIO mode. Hardware Overriding: Note that hardware overrides MMIO setting for AYA_CTL and sets it CLOSED during the INIT_SHORT state. This register is wired to the hard IP directly (no MUX required in soft IP).
      0=OPEN (Opens second part of AYA switch. Enables isolation on AYA if AYA_EN is also OPEN_ISOLATED.); 1=CLOSED (N/A); 2=CHOP_TWO_PHASE (chop == 0 ? ph0 : ph1); 3=CHOP_FOUR_PHASE (chop == 0 ? ph1 : ph3); 4=CHOP_MPSC_D (chop == 0 ? ph3 : ph1); 5=CHOP_MPRX (chop == 0 ? ph1 : ph0); 6=PH0 (N/A); 7=PH2 (N/A)
    [4] CBCD — CSD Bus B to CSD Bus D Switch. Hardware Overriding: Note that hardware overrides MMIO setting for CBCD and sets it CLOSED during the INIT_SHORT state.
      0=OPEN (N/A); 1=CLOSED (N/A)
    [2] CACC — CSD Bus A to CSD Bus C Switch. Hardware Overriding: Note that hardware overrides MMIO setting for CACC and sets it CLOSED during the INIT_SHORT state.
      0=OPEN (N/A); 1=CLOSED (N/A)
    [0] CACB — CSD Bus A to CSD Bus B Switch. Hardware Overriding: Note that hardware overrides MMIO setting for CACB and sets it CLOSED during the INIT_SHORT state.
      0=OPEN (N/A); 1=CLOSED (N/A)
  0x0C SW_SEL_COMP — MSC Comparator Switch Control
    [31] HALF_WAVE_EN — Enables halfwave mode in the comparator where reference is vdda_q. Firmware Rule: When HALF_WAVE_EN = ENABLED, CHOP_POL must be programmed to 1 in the case where INIT_MODE = REFERENCE_VDDA.
      0=DISABLED (N/A); 1=ENABLED (N/A)
    [22] CMF — Comparator Minus Terminal to Reference Filter Switch
      0=OPEN (N/A); 1=CLOSED (N/A)
    [20] CMG — Comparator Minus Terminal to vssa_q Switch. Firmware Rule: Do not program CMV and CMG such that they are closed simultaneously.
      0=OPEN (N/A); 1=CLOSED (N/A)
    [18] CMV — Comparator Minus Terminal to vdda_q Switch. Firmware Rule: Do not program CMV and CMG such that they are closed simultaneously.
      0=OPEN (N/A); 1=CLOSED (N/A)
    [16] CMCS4 — Comparator Minus Terminal to CMOD4 Sense Switch
      0=OPEN (N/A); 1=CLOSED (N/A)
    [14] CMCS2 — Comparator Minus Terminal to CMOD2 Sense Switch
      0=OPEN (N/A); 1=CLOSED (N/A)
    [12] CPF — Comparator Plus Terminal to Reference Filter Switch
      0=OPEN (N/A); 1=CLOSED (N/A)
    [10] CMCB — Comparator Minus Terminal to CSD Bus B Switch
      0=OPEN (N/A); 1=CLOSED (N/A)
    [8] CPCB — Comparator Plus Terminal to CSD Bus B Switch
      0=OPEN (N/A); 1=CLOSED (N/A)
    [6] CPCA — Comparator Plus Terminal to CSD Bus A Switch
      0=OPEN (N/A); 1=CLOSED (N/A)
    [4] CPMA — Comparator Plus Terminal to AMUXBUSA Switch
      0=OPEN (N/A); 1=CLOSED (N/A)
    [2] CPCS3 — Comparator Plus Terminal to CMOD3 Sense Switch
      0=OPEN (N/A); 1=CLOSED (N/A)
    [0] CPCS1 — Comparator Plus Terminal to CMOD1 Sense Switch
      0=OPEN (N/A); 1=CLOSED (N/A)
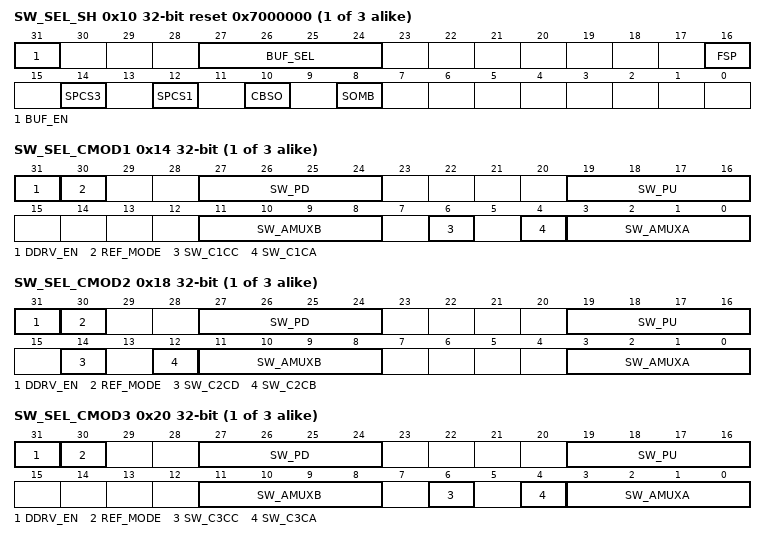
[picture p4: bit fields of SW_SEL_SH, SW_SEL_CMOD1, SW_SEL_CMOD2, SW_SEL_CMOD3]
  0x10 SW_SEL_SH reset 0x7000000 — Shielding Switch Control
    [31] BUF_EN — Enable the shield buffer. '0': Off '1': On
      0=DISABLED (N/A); 1=ENABLED (N/A)
    [27:24] BUF_SEL — Selects value of compensation capacitance in shield buffer.
    [16] FSP — Reference Filter to Shield Positive Terminal Switch
      0=OPEN (N/A); 1=CLOSED (N/A)
    [14] SPCS3 — Shield Minus Terminal to CMOD3 Sense Switch
      0=OPEN (N/A); 1=CLOSED (N/A)
    [12] SPCS1 — Shield Minus Terminal to CMOD1 Sense Switch
      0=OPEN (N/A); 1=CLOSED (N/A)
    [10] CBSO — CSD Bus B to Shield OpAmp Switch
      0=OPEN (N/A); 1=CLOSED (N/A)
    [8] SOMB — Shield OpAmp to AMUXBUSB Switch. Hardware Overriding: See CMOD_SEL and INIT_MODE for INIT_CMOD phase half-wave initialisation behaviour. If full wave (CMOD_SEL = CMOD_12||CMOD_34), then during INIT_CMOD, SOMB is set CLOSED.
      0=OPEN (N/A); 1=CLOSED (N/A)
  0x14 SW_SEL_CMOD1 — CMOD Switch Control 1
    [31] DDRV_EN — CMOD1 digital driver enable in MSC specific GPIO. Firmware Rule: When using the digital driver, the GPIO MSC analog cannot be used (GPIO port register MSC_ANA.DATAx for port pin x should be set 0).
      0=DISABLED (N/A); 1=ENABLED (N/A)
    [30] REF_MODE — CMOD1 is used as a reference in scenario where CMOD can be re-purposed when not used as a CMOD. Hardware Overriding: If REF_MODE = 0 and (CMOD_SEL != CMOD_1 && CMOD_SEL != CMOD_12), SW_AMUXA, SW_AMUXB, SW_PU and SW_PD are all forced OPEN duing PRO_OFFSET, PRO_WAIT, EPILOGUE and POST_EPI to disconnect the sensor.
      0=DISABLED (N/A); 1=ENABLED (N/A)
    [27:24] SW_PD — CMOD1 to vssa_q Switch. Switch exists in MSC specific GPIO. Firmware Rule: Do not program SW_PU and SW_PD such that they are closed simultaneously. Hardware Overriding: If this CMOD is spare and is a FW CSX TXP pin (SW_PU == PH0X && SW_PD == PH1X), SW_PU is CLOSED during INIT_CMOD and INIT_SHORT if in full wave mode (CMOD_SEL = CMOD_34 && INIT_MODE = REFERENCE_VDDA).
      values as SW_SEL_CSW[0].SW_PD
    [19:16] SW_PU — CMOD1 to vdda_q Switch. Switch exists in MSC specific GPIO. Also drives the MSC specific GPIO digital driver (enable controlled by DDRV_EN). Hardware Overriding: See INIT_MODE and CMOD_SEL for INIT_CMOD phase overriding. If this CMOD is spare and is a FW CSX TXN pin (SW_PU == PH1X && SW_PD == PH0X), SW_PU is CLOSED during INIT_CMOD and INIT_SHORT if in full wave mode (CMOD_SEL = CMOD_34 && INIT_MODE = REFERENCE_VDDA). Firmware Rule: Do not program SW_PU and SW_PD such that they are closed simultaneously.
      values as SW_SEL_CSW[0].SW_PU
    [11:8] SW_AMUXB — CMOD1 to AMUXBUSB Switch. Switch exists in MSC specific GPIO. Hardware Overriding: See INIT_MODE and CMOD_SEL for INIT_CMOD phase overriding. If CMOD1 is being used as a sensor (SW_AMUXA != OPEN), and in full wave mode (CMOD_SEL = CMOD_34 && INIT_MODE = REFERENCE_VDDA), SW_AMUXB is closed during INIT_CMOD.
      values as SW_SEL_CSW[0].SW_AMUXB
    [6] SW_C1CC — CMOD1 to CSD Bus C Switch. Switch exists in MSCv3LP hard IP. Hardware Overriding: During INIT_SHORT (used for full-wave scanning) if CMOD_SEL = CMOD_12, hardware sets C1CC = CLOSED. See INIT_MODE and CMOD_SEL for INIT_CMOD phase overriding (half-wave with VREF reference).
      0=OPEN (N/A); 1=CLOSED (N/A)
    [4] SW_C1CA — CMOD1 to CSD Bus A Switch. Switch exists in MSCv3LP hard IP. Hardware Overriding: During INIT_SHORT (used for full-wave scanning) if CMOD_SEL = CMOD_12, hardware sets C1CA = CLOSED. See INIT_MODE and CMOD_SEL for INIT_CMOD phase overriding (half-wave with VREF reference).
      0=OPEN (N/A); 1=CLOSED (N/A)
    [3:0] SW_AMUXA — CMOD1 to AMUXBUSA Switch. Switch exists in MSC specific GPIO. Hardware Overriding: During INIT_SHORT (used for full-wave scanning) if CMOD_SEL = CMOD_12, hardware sets CMOD1 SW_AMUXA = CLOSED. If Cmod1 not used as a Cmod (CMOD_SEL != CMOD_1 && CMOD_SEL != CMOD_12) then can use it as a spare sensor. In this case hardware overrides MMIO setting for SW_AMUXA and sets it CLOSED during the INIT_SHORT state if MMIO has programmed SW_AMUXA != OPEN.
      values as SW_SEL_CSW[0].SW_AMUXA
  0x18 SW_SEL_CMOD2 — CMOD Switch Control 2
    [31] DDRV_EN — CMOD2 digital driver enable in MSC specific GPIO. Firmware Rule: When using the digital driver, the GPIO MSC analog cannot be used (GPIO port register MSC_ANA.DATAx for port pin x should be set 0).
      0=DISABLED (N/A); 1=ENABLED (N/A)
    [30] REF_MODE — CMOD2 is used as a reference in scenario where CMOD can be re-purposed when not used as a CMOD. Hardware Overriding: If REF_MODE = 0 and (CMOD_SEL != CMOD_12), SW_AMUXA, SW_AMUXB, SW_PU and SW_PD are all forced OPEN duing PRO_OFFSET, PRO_WAIT, EPILOGUE and POST_EPI to disconnect the sensor.
      0=DISABLED (N/A); 1=ENABLED (N/A)
    [27:24] SW_PD — CMOD2 to vssa_q Switch. Switch exists in MSC specific GPIO. Hardware Overriding: See INIT_MODE and CMOD_SEL for INIT_CMOD phase overriding. If this CMOD is spare and is a FW CSX TXP pin (SW_PU == PH0X && SW_PD == PH1X), SW_PU is CLOSED during INIT_CMOD and INIT_SHORT if in full wave mode (CMOD_SEL = CMOD_34 && INIT_MODE = REFERENCE_VDDA). Firmware Rule: Do not program SW_PU and SW_PD such that they are closed simultaneously.
      values as SW_SEL_CSW[0].SW_PD
    [19:16] SW_PU — CMOD2 to vdda_q Switch. Switch exists in MSC specific GPIO. Also drives the MSC specific GPIO digital driver (enable controlled by DDRV_EN). Firmware Rule: Do not program SW_PU and SW_PD such that they are closed simultaneously. Hardware Overriding: If this CMOD is spare and is a FW CSX TXN pin (SW_PU == PH1X && SW_PD == PH0X), SW_PU is CLOSED during INIT_CMOD and INIT_SHORT if in full wave mode (CMOD_SEL = CMOD_34 && INIT_MODE = REFERENCE_VDDA).
      values as SW_SEL_CSW[0].SW_PU
    [14] SW_C2CD — CMOD2 to CSD Bus D Switch. Switch exists in MSCv3LP hard IP. During INIT_SHORT (used for full-wave scanning) if CMOD_SEL = CMOD_12, hardware sets SW_C2CD = CLOSED.
      0=OPEN (N/A); 1=CLOSED (N/A)
    [12] SW_C2CB — CMOD2 to CSD Bus B Switch. Switch exists in MSCv3LP hard IP. During INIT_SHORT (used for full-wave scanning) if CMOD_SEL = CMOD_12, hardware sets SW_C2CB = CLOSED.
      0=OPEN (N/A); 1=CLOSED (N/A)
    [11:8] SW_AMUXB — CMOD2 to AMUXBUSB Switch. Switch exists in MSC specific GPIO. Hardware Overriding: If CMOD2 is being used as a sensor (SW_AMUXA != OPEN), and in full wave mode (CMOD_SEL = CMOD_34 && INIT_MODE = REFERENCE_VDDA), SW_AMUXB is closed during INIT_CMOD.
      values as SW_SEL_CSW[0].SW_AMUXB
    [3:0] SW_AMUXA — CMOD2 to AMUXBUSA Switch. Switch exists in MSC specific GPIO. Hardware Overriding: During INIT_SHORT (used for full-wave scanning) if CMOD_SEL = CMOD_12, hardware sets CMOD2 SW_AMUXA = CLOSED. If Cmod2 not used as a Cmod (CMOD_SEL != CMOD_12) then can use it as a spare sensor. In this case hardware overrides MMIO setting for SW_AMUXA and sets it CLOSED during the INIT_SHORT state if MMIO has programmed SW_AMUXA != OPEN.
      values as SW_SEL_CSW[0].SW_AMUXA
  0x20 SW_SEL_CMOD3 — CMOD Switch Control 3
    [31] DDRV_EN — CMOD3 digital driver enable in MSC specific GPIO. Firmware Rule: When using the digital driver, the GPIO MSC analog cannot be used (GPIO port register MSC_ANA.DATAx for port pin x should be set 0).
      0=DISABLED (N/A); 1=ENABLED (N/A)
    [30] REF_MODE — CMOD3 is used as a reference in scenario where CMOD can be re-purposed when not used as a CMOD. Hardware Overriding: If REF_MODE = 0 and (CMOD_SEL != CMOD_3 && CMOD_SEL != CMOD_34), SW_AMUXA, SW_AMUXB, SW_PU and SW_PD are all forced OPEN duing PRO_OFFSET, PRO_WAIT, EPILOGUE and POST_EPI to disconnect the sensor.
      0=DISABLED (N/A); 1=ENABLED (N/A)
    [27:24] SW_PD — CMOD3 to vssa_q Switch. Switch exists in MSC specific GPIO. Firmware Rule: Do not program SW_PU and SW_PD such that they are closed simultaneously. Hardware Overriding: If this CMOD is spare and is a FW CSX TXP pin (SW_PU == PH0X && SW_PD == PH1X), SW_PU is CLOSED during INIT_CMOD and INIT_SHORT if in full wave mode (CMOD_SEL = CMOD_12 && INIT_MODE = REFERENCE_VDDA).
      values as SW_SEL_CSW[0].SW_PD
    [19:16] SW_PU — CMOD3 to vdda_q Switch. Switch exists in MSC specific GPIO. Also drives the MSC specific GPIO digital driver (enable controlled by DDRV_EN). Hardware Overriding: See INIT_MODE and CMOD_SEL for INIT_CMOD phase overriding. If this CMOD is spare and is a FW CSX TXN pin (SW_PU == PH1X && SW_PD == PH0X), SW_PU is CLOSED during INIT_CMOD and INIT_SHORT if in full wave mode (CMOD_SEL = CMOD_12 && INIT_MODE = REFERENCE_VDDA). Firmware Rule: Do not program SW_PU and SW_PD such that they are closed simultaneously.
      values as SW_SEL_CSW[0].SW_PU
    [11:8] SW_AMUXB — CMOD3 to AMUXBUSB Switch. Switch exists in MSC specific GPIO. Hardware Overriding: See INIT_MODE and CMOD_SEL for INIT_CMOD phase overriding. If CMOD3 is being used as a sensor (SW_AMUXA != OPEN), and in full wave mode (CMOD_SEL = CMOD_12 && INIT_MODE=REFERENCE_VDDA), SW_AMUXB is closed during INIT_CMOD.
      values as SW_SEL_CSW[0].SW_AMUXB
    [6] SW_C3CC — CMOD3 to CSD Bus C Switch. Switch exists in MSCv3LP hard IP. Hardware Overriding: During INIT_SHORT (used for full-wave scanning) if CMOD_SEL = CMOD_34, hardware sets C3CC = CLOSED. See INIT_MODE and CMOD_SEL for INIT_CMOD phase overriding (half-wave with VREF reference).
      0=OPEN (N/A); 1=CLOSED (N/A)
    [4] SW_C3CA — CMOD3 to CSD Bus A Switch. Switch exists in MSCv3LP hard IP. Hardware Overriding: During INIT_SHORT (used for full-wave scanning) if CMOD_SEL = CMOD_34, hardware sets C3CA = CLOSED. See INIT_MODE and CMOD_SEL for INIT_CMOD phase overriding (half-wave with VREF reference).
      0=OPEN (N/A); 1=CLOSED (N/A)
    [3:0] SW_AMUXA — CMOD3 to AMUXBUSA Switch. Switch exists in MSC specific GPIO. Hardware Overriding: During INIT_SHORT (used for full-wave scanning) if CMOD_SEL = CMOD_34, hardware sets CMOD3 SW_AMUXA = CLOSED. If Cmod3 not used as a Cmod (CMOD_SEL != CMOD_3 && CMOD_SEL != CMOD_34) then can use it as a spare sensor. In this case hardware overrides MMIO setting for SW_AMUXA and sets it CLOSED during the INIT_SHORT state if MMIO has programmed SW_AMUXA != OPEN.
      values as SW_SEL_CSW[0].SW_AMUXA
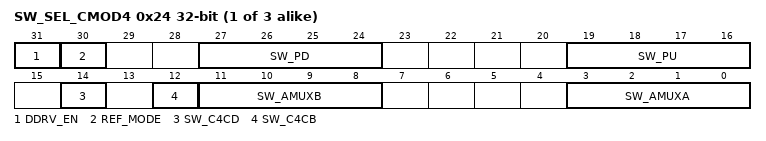
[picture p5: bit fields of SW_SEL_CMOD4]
  0x24 SW_SEL_CMOD4 — CMOD Switch Control 4
    [31] DDRV_EN — CMOD4 digital driver enable in MSC specific GPIO. Firmware Rule: When using the digital driver, the GPIO MSC analog cannot be used (GPIO port register MSC_ANA.DATAx for port pin x should be set 0).
      0=DISABLED (N/A); 1=ENABLED (N/A)
    [30] REF_MODE — CMOD4 is used as a reference in scenario where CMOD can be re-purposed when not used as a CMOD. Hardware Overriding: If REF_MODE = 0 and (CMOD_SEL != CMOD_34), SW_AMUXA, SW_AMUXB, SW_PU and SW_PD are all forced OPEN duing PRO_OFFSET, PRO_WAIT, EPILOGUE and POST_EPI to disconnect the sensor.
      0=DISABLED (N/A); 1=ENABLED (N/A)
    [27:24] SW_PD — CMOD4 to vssa_q Switch. Switch exists in MSC specific GPIO. Hardware Overriding: See INIT_MODE and CMOD_SEL for INIT_CMOD phase overriding. If this CMOD is spare and is a FW CSX TXP pin (SW_PU == PH0X && SW_PD == PH1X), SW_PU is CLOSED during INIT_CMOD and INIT_SHORT if in full wave mode (CMOD_SEL = CMOD_12 && INIT_MODE = REFERENCE_VDDA). Firmware Rule: Do not program SW_PU and SW_PD such that they are closed simultaneously.
      values as SW_SEL_CSW[0].SW_PD
    [19:16] SW_PU — CMOD4 to vdda_q Switch. Switch exists in MSC specific GPIO. Also drives the MSC specific GPIO digital driver (enable controlled by DDRV_EN). Firmware Rule: Do not program SW_PU and SW_PD such that they are closed simultaneously. Hardware Overriding: If this CMOD is spare and is a FW CSX TXN pin (SW_PU == PH1X && SW_PD == PH0X), SW_PU is CLOSED during INIT_CMOD and INIT_SHORT if in full wave mode (CMOD_SEL = CMOD_12 && INIT_MODE = REFERENCE_VDDA).
      values as SW_SEL_CSW[0].SW_PU
    [14] SW_C4CD — CMOD4 to CSD Bus D Switch. Switch exists in MSCv3LP hard IP. During INIT_SHORT (used for full-wave scanning) if CMOD_SEL = CMOD_34, hardware sets SW_C4CD = CLOSED.
      0=OPEN (N/A); 1=CLOSED (N/A)
    [12] SW_C4CB — CMOD4 to CSD Bus B Switch. Switch exists in MSCv3LP hard IP. During INIT_SHORT (used for full-wave scanning) if CMOD_SEL = CMOD_34, hardware sets SW_C4CB = CLOSED.
      0=OPEN (N/A); 1=CLOSED (N/A)
    [11:8] SW_AMUXB — CMOD4 to AMUXBUSB Switch. Switch exists in MSC specific GPIO. Hardware Overriding: If CMOD4 is being used as a sensor (SW_AMUXA != OPEN), and in full wave mode (CMOD_SEL = CMOD_12 && INIT_MODE=REFERENCE_VDDA), SW_AMUXB is closed during INIT_CMOD.
      values as SW_SEL_CSW[0].SW_AMUXB
    [3:0] SW_AMUXA — CMOD4 to AMUXBUSA Switch. Switch exists in MSC specific GPIO. Hardware Overriding: During INIT_SHORT (used for full-wave scanning) if CMOD_SEL = CMOD_34, hardware sets CMOD4 SW_AMUXA = CLOSED. If Cmod4 not used as a Cmod (CMOD_SEL != CMOD_34) then can use it as a spare sensor. In this case hardware overrides MMIO setting for SW_AMUXA and sets it CLOSED during the INIT_SHORT state if MMIO has programmed SW_AMUXA != OPEN.
      values as SW_SEL_CSW[0].SW_AMUXA
